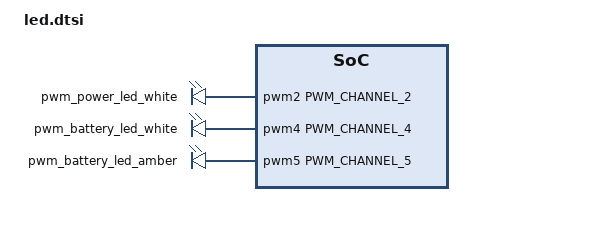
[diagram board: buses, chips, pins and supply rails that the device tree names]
/* Copyright 2025 The ChromiumOS Authors
 * Use of this source code is governed by a BSD-style license that can be
 * found in the LICENSE file.
 */

 / {
	pwmleds {
		compatible = "pwm-leds";

		pwm_power_led_white: power_led_l {
			pwms = <&pwm2 PWM_CHANNEL_2 PWM_HZ(324)
				PWM_POLARITY_INVERTED>;
		};
		pwm_battery_led_white: charge_led_white_l {
			pwms = <&pwm4 PWM_CHANNEL_4 PWM_HZ(324)
				PWM_POLARITY_INVERTED>;
		};
		pwm_battery_led_amber: charge_led_amber_l {
			pwms = <&pwm5 PWM_CHANNEL_5 PWM_HZ(324)
				PWM_POLARITY_INVERTED>;
		};
	};

	cros-pwmleds {
		compatible = "cros-ec,pwm-leds";

		leds = <&pwm_power_led_white>;
		leds = <&pwm_battery_led_white>;
		leds = <&pwm_battery_led_amber>;
	};
};
